# nrf7140_application register map
Vendor: Nordic Semiconductor; Series: nRF71; File version: 1
CPU: CM33 r0p4, little endian, MPU, FPU, 3 interrupt priority bits, 480 interrupts, 8 SAU regions
Registers are 32-bit, read-write, reset 0x0 unless marked. A register's access mark holds for its fields unless they carry their own. Offsets are from the block's base; [hi:lo] are bit positions; lines under a group give offsets from that group; {n}, {i} and the like mark numbered series.

## GLOBAL_GSI_NS (part 3 of 3) — GSI
Base 0x49008000
0x2000 CSI2 group — Unspecified
  0x00 VERSION reset 0x30313534 — Contains the version of DWC_mipi_csi2_host coded in 32-bit ASCII code.
    [31:0] VERSION ro — This field indicates the version of the DWC_mipi_csi2_host.
  0x04 NLANES reset 0x1 — Configures the number of active lanes that the DWC_mipi_csi2_host uses to receive the camera device data.
    [2:0] NLANES — This can only be updated when the PHY lane is in stopstate.Number of active data lanes:
      0=DATALANE1 (1 Data Lane); 1=DATALANE2 (2 Data Lanes); 2=DATALANE3 (3 Data Lanes); {v}=DATALANE{v+1} ({v+1} Data Lanes - Only on D-PHY) (v=3..7)
  0x08 CSI2RESETN — Controls the DWC_mipi_csi2_host logic reset state. When activated, the internal logic of the controller goes into the reset state. The configuration is not reset to default values with this register, instead, only the internal controller logic is affected.
    [0] CSI2RESETN — DWC_mipi_csi2_host reset output. Active Low.
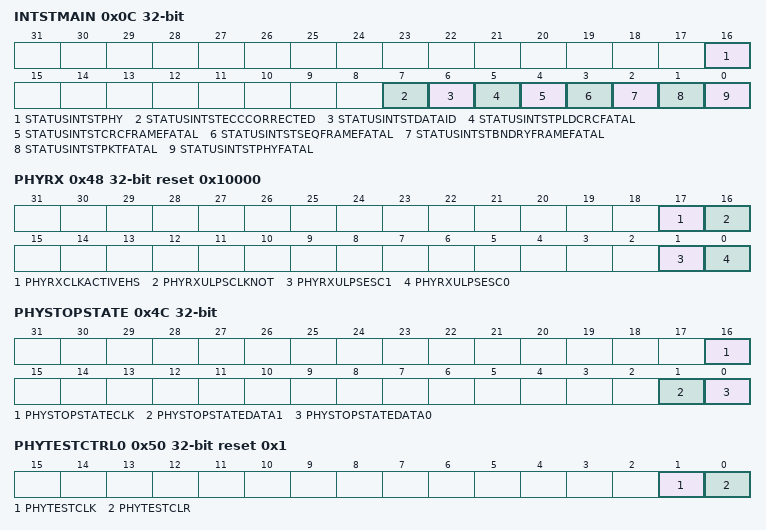
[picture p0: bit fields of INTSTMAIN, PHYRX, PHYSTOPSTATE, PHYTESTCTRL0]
  0x0C INTSTMAIN — Contains the status of individual interrupt sources, regardless of the contents of the associated interrupt mask registers, so it is possible to service the interrupt status registers by polling. Reading INT_ST_MAIN register clears the interrupt pin.
    [16] STATUSINTSTPHY ro — Status of int_st_phy.
    [7] STATUSINTSTECCCORRECTED ro — Status of int_st_ecc_corrected.
    [6] STATUSINTSTDATAID ro — Status of int_st_data_id.
    [5] STATUSINTSTPLDCRCFATAL ro — Status of int_st_pld_crc_fatal.
    [4] STATUSINTSTCRCFRAMEFATAL ro — Status of int_st_crc_frame_fatal.
    [3] STATUSINTSTSEQFRAMEFATAL ro — Status of int_st_seq_frame_fatal.
    [2] STATUSINTSTBNDRYFRAMEFATAL ro — Status of int_st_bndry_frame_fatal.
    [1] STATUSINTSTPKTFATAL ro — Status of int_st_pkt_fatal.
    [0] STATUSINTSTPHYFATAL ro — Status of int_st_phy_fatal.
  0x40 PHYSHUTDOWNZ — Controls the PHY Shutdown mode. In this state, the PHY sets the analog and digital circuitry in the Reset state.
    [0] PHYSHUTDOWNZ — Shutdown input. This line is used to place the complete macro in power down. All analog blocks are in power down mode and digital logic is cleared. Active Low.
  0x44 DPHYRSTZ — Controls the PHY Reset mode. In this state, the PHY sets the digital circuitry in the Reset State.
    [0] DPHYRSTZ — PHY reset output. Active Low.
  0x48 PHYRX reset 0x10000 — Contains the status of RX-related signals from PHY:
    [17] PHYRXCLKACTIVEHS ro — Indicates that D-PHY clock lane is actively receiving a DDR clock
    [16] PHYRXULPSCLKNOT ro — Active Low. This signal indicates that D-PHY Clock Lane module has entered the Ultra Low Power state
    [1] PHYRXULPSESC1 ro — Lane module 1 has entered the Ultra Low Power mode
    [0] PHYRXULPSESC0 ro — Lane module 0 has entered the Ultra Low Power mode.
  0x4C PHYSTOPSTATE — Contains the STOPSTATE signal status from PHY.
    [16] PHYSTOPSTATECLK ro — D-PHY Clock lane in Stop state
    [1] PHYSTOPSTATEDATA1 ro — Data lane 1 in Stop state
    [0] PHYSTOPSTATEDATA0 ro — Data lane 0 in Stop state.
  0x50 PHYTESTCTRL0 reset 0x1 — Control for vendor specific interface in the PHY.
    [1] PHYTESTCLK — Clock to capture testdin bus contents into the macro, with testen signal controlling the operation selection.
    [0] PHYTESTCLR — When active, performs vendor specific interface initialization.
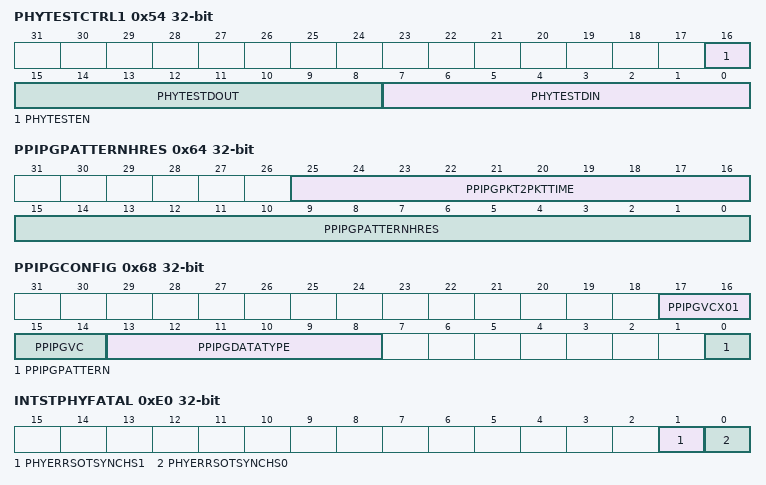
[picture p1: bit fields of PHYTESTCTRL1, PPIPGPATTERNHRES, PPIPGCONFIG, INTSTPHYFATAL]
  0x54 PHYTESTCTRL1 — Control for vendor specific interface in the PHY.
    [16] PHYTESTEN — When asserted high, it configures an address write operation on the falling edge of testclk. When asserted low, it configures a data write operation on the rising edge of testclk.
    [15:8] PHYTESTDOUT ro — Vendor-specific 8-bit data output for reading data and other probing functionalities.
    [7:0] PHYTESTDIN — Test interface 8-bit data input for programming internal registers and accessing test functionalities.
  0x60 PPIPGPATTERNVRES — This register configures the PPI pattern Generator's pattern vertical resolution.
    [15:0] PPIPGPATTERNVRES
  0x64 PPIPGPATTERNHRES — This register configures the PPI pattern Generator's pattern horizontal resolution.
    [25:16] PPIPGPKT2PKTTIME — This register configures the PPI pattern Generator's packet-to-packet time.
    [15:0] PPIPGPATTERNHRES — This register configures the PPI pattern Generator's pattern horizontal resolution.
  0x68 PPIPGCONFIG — This register configures the PPI pattern Generator.
    [17:16] PPIPGVCX01 — This register configures the PPI pattern Generator's virtual channel extension.
    [15:14] PPIPGVC — This register configures the PPI pattern Generator's virtual channel.
    [13:8] PPIPGDATATYPE — This register configures the PPI pattern Generator's data type.
    [0] PPIPGPATTERN — This register configures the PPI pattern Generator's pattern:
      0=VERTICAL (Vertical Pattern); 1=HORIZONTAL (Horizontal Pattern)
  0x6C PPIPGENABLE — This register enables PPI pattern Generator.
    [0] PPIPGENABLE
  0x70 PPIPGSTATUS — This register indicates PPI Pattern Generator Status.
    [0] PPIPGSTATUS ro — PPI Pattern Generator status:
      0=INACTIVE (PPI PG is inactive); 1=ACTIVE (PPI PG is running)
  0xC8 VCEXTENSION — This register activates extra bits for virtual channel. The Virtual Channel Extension (VCX) field is common to both options, but is a 2-bit field for D-PHY and a 3-bit field for C-PHY.
    [0] VCX — This field indicates status of Virtual Channel Extension:
  0xCC PHYCAL — Contains the CALIBRATION signal status from Synopsys D-PHY.
    [0] RXSKEWCALHS ro — A low-to-high transition on rxskewcalhs signal means that the PHY has initiated the de-skew calibration.
  0xE0 INTSTPHYFATAL — Groups the fatal interruptions caused by PHY Packet discarded.
    [1] PHYERRSOTSYNCHS1 ro — Start of transmission error on data lane 1 (no synchronization achieved)
    [0] PHYERRSOTSYNCHS0 ro — Start of transmission error on data lane 0 (no synchronization achieved).
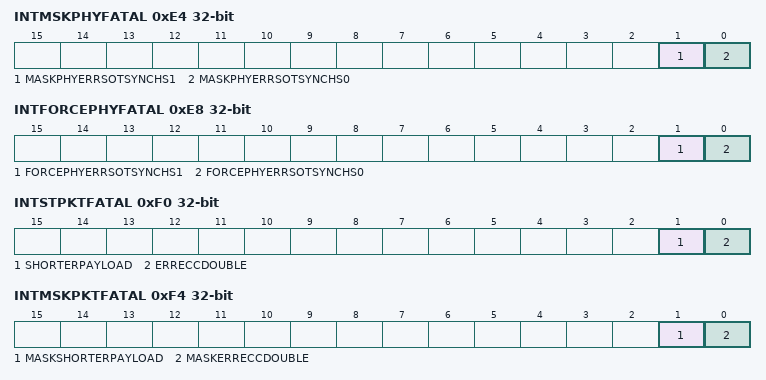
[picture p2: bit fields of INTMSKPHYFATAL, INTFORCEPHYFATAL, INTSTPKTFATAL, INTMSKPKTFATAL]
  0xE4 INTMSKPHYFATAL — Interrupt mask for INT_ST_PHY_FATAL controls which interrupt status bits trigger the interrupt pin. Bit at 1 - Enable the interrupt source. Bit at 0 - Interrupt source is masked.
    [1] MASKPHYERRSOTSYNCHS1 — Mask for phy_errsotsynchs_1
    [0] MASKPHYERRSOTSYNCHS0 — Mask for phy_errsotsynchs_0.
  0xE8 INTFORCEPHYFATAL — Interrupt Force register is used for test purposes, and allows triggering INT_ST_PHY_FATAL interrupt events individually, without the need to activate the conditions that trigger the interrupt sources, since it may be extremely complex to generate stimuli for that purpose. This register is auto-clear.
    [1] FORCEPHYERRSOTSYNCHS1, [0] FORCEPHYERRSOTSYNCHS0
  0xF0 INTSTPKTFATAL — Groups the fatal interruption related with Packet construction. Packet discarded.
    [1] SHORTERPAYLOAD ro — D-PHY mode: Reported greater WC than received, unrecoverable.
    [0] ERRECCDOUBLE ro — D-PHY mode: Header ECC contains at least 2 errors, unrecoverable.
  0xF4 INTMSKPKTFATAL — Interrupt mask for INT_ST_PKT_FATAL controls which interrupt status bits trigger the interrupt pin. Bit at 1 - Enable the interrupt source. Bit at 0 - Interrupt source is masked.
    [1] MASKSHORTERPAYLOAD — Mask for shorter_payload.
    [0] MASKERRECCDOUBLE — Mask for err_ecc_double.
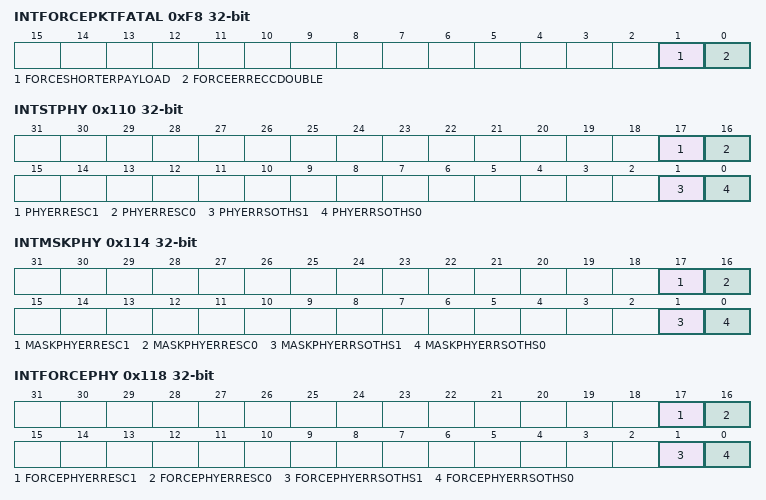
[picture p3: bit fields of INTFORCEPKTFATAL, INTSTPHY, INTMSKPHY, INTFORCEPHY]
  0xF8 INTFORCEPKTFATAL — Interrupt force register is used for test purposes, and allows triggering INT_ST_PKT_FATAL interrupt events individually, without the need to activate the conditions that trigger the interrupt sources, since it may be extremely complex to generate stimuli for that purpose. This register is auto-clear.
    [1] FORCESHORTERPAYLOAD, [0] FORCEERRECCDOUBLE
  0x110 INTSTPHY — Interruption caused by PHY.
    [17] PHYERRESC1 ro — Escape Entry Error on data lane 1
    [16] PHYERRESC0 ro — Escape Entry Error on data lane 0.
    [1] PHYERRSOTHS1 ro — Start of transmission error on data lane 1 (synchronization can still be achieved)
    [0] PHYERRSOTHS0 ro — Start of transmission error on data lane 0 (synchronization can still be achieved).
  0x114 INTMSKPHY — Interrupt mask for INT_ST_PHY controls which interrupt status bits trigger the interrupt pin. Bit at 1 - Enable the interrupt source. Bit at 0 - Interrupt source is masked.
    [17] MASKPHYERRESC1 — Mask for phy_erresc_1
    [16] MASKPHYERRESC0 — Mask for phy_erresc_0.
    [1] MASKPHYERRSOTHS1 — Mask for phy_errsoths_1
    [0] MASKPHYERRSOTHS0 — Mask for phy_errsoths_0.
  0x118 INTFORCEPHY — Interrupt force register is used for test purposes, and allows triggering INT_ST_PHY interrupt events individually. There is no need to activate the conditions that trigger the interrupt sources, because it may be extremely complex to generate stimuli for that purpose. This register is auto-clear.
    [17] FORCEPHYERRESC1, [16] FORCEPHYERRESC0, [1] FORCEPHYERRSOTHS1, [0] FORCEPHYERRSOTHS0
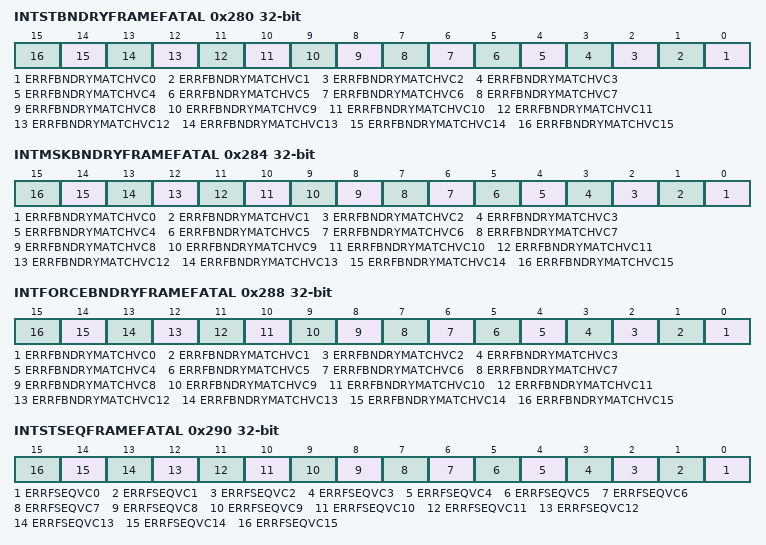
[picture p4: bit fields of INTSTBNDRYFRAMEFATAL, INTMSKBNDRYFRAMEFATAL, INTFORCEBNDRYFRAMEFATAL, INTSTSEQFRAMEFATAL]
  0x280 INTSTBNDRYFRAMEFATAL — Fatal interruption related with matching Frame Start with Frame End for a specific virtual channel.
    [n] ERRFBNDRYMATCHVC{n} ro (n=0..15) — Error matching Frame Start with Frame End for virtual channel {n}.
  0x284 INTMSKBNDRYFRAMEFATAL — Interrupt mask for INT_ST_BNDRY_FRAME_FATAL controls which interrupt status bits trigger the interrupt pin. Bit at 1 - Enable the interrupt source. Bit at 0 - Interrupt source is masked.
    [n] ERRFBNDRYMATCHVC{n} (n=0..15) — Mask for err_f_bndry_match_vc{n}.
  0x288 INTFORCEBNDRYFRAMEFATAL — Interrupt force register is used for test purposes, and allows triggering INT_ST_BNDRY_FRAME_FATAL interrupt events individually, without the need to activate the conditions that trigger the interrupt sources, since it may be extremely complex to generate stimuli for that purpose. This register is auto-clear.
    [n] ERRFBNDRYMATCHVC{n} (n=0..15) — Force err_f_bndry_match_vc{n}.
  0x290 INTSTSEQFRAMEFATAL — Fatal interruption related with incorrect Frame sequence for a specific virtual channel.
    [n] ERRFSEQVC{n} ro (n=0..15) — Incorrect Frame sequence detected in virtual channel {n}.
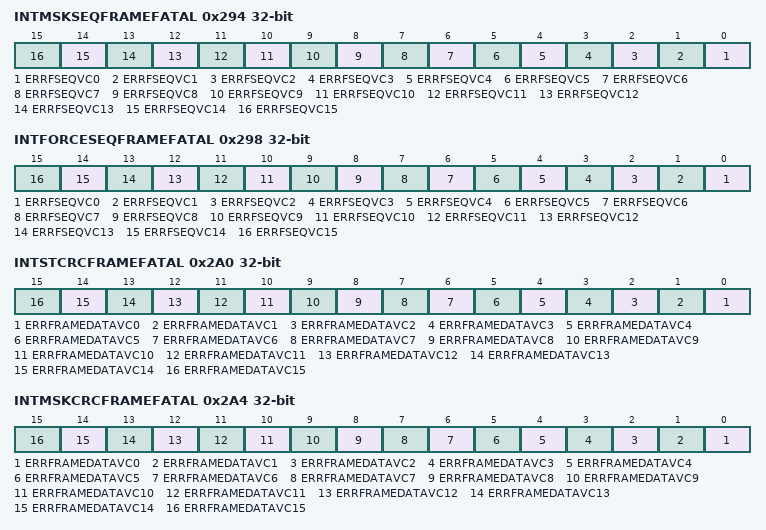
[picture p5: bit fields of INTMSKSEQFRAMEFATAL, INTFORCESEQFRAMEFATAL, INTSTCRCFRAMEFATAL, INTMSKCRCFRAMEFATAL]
  0x294 INTMSKSEQFRAMEFATAL — Interrupt mask for INT_ST_SEQ_FRAME_FATAL controls which interrupt status bits trigger the interrupt pin. Bit at 1 - Enable the interrupt source. Bit at 0 - Interrupt source is masked.
    [n] ERRFSEQVC{n} (n=0..15) — Mask for err_f_seq_vc{n}.
  0x298 INTFORCESEQFRAMEFATAL — Interrupt force register is used for test purposes, and allows triggering INT_ST_SEQ_FRAME_FATAL interrupt events individually. There is no need to activate the conditions that trigger the interrupt sources, because it may be extremely complex to generate stimuli for that purpose. This register is auto-clear.
    [n] ERRFSEQVC{n} (n=0..15) — Force err_f_seq_vc{n}.
  0x2A0 INTSTCRCFRAMEFATAL — Fatal interruption related with Frames with at least one CRC error for a specific virtual channel.
    [n] ERRFRAMEDATAVC{n} ro (n=0..15) — Last received Frame in virtual channel {n}, had at least one CRC error.
  0x2A4 INTMSKCRCFRAMEFATAL — Interrupt mask for INT_ST_CRC_FRAME_FATAL controls which interrupt status bits trigger the interrupt pin. Bit at 1 - Enable the interrupt source. Bit at 0 - Interrupt source is masked.
    [n] ERRFRAMEDATAVC{n} (n=0..15) — Mask for err_frame_data_vc{n}.
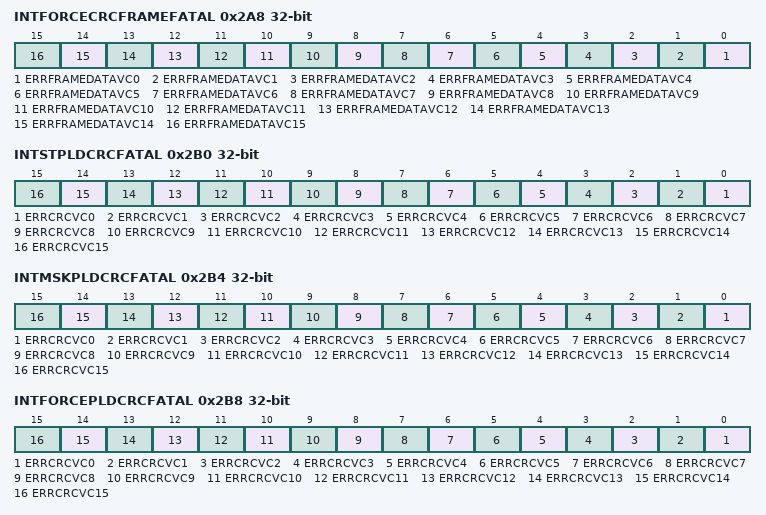
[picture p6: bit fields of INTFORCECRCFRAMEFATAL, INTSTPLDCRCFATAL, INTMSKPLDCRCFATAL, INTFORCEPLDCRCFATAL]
  0x2A8 INTFORCECRCFRAMEFATAL — Interrupt force register is used for test purposes, and allows triggering INT_ST_CRC_FRAME_FATAL interrupt events individually. There is no need to activate the conditions that trigger the interrupt sources, because it may be extremely complex to generate stimuli for that purpose. This register is auto-clear.
    [n] ERRFRAMEDATAVC{n} (n=0..15) — Force err_frame_data_vc{n}.
  0x2B0 INTSTPLDCRCFATAL — Fatal interruption related with Payload Checksum error.
    [n] ERRCRCVC{n} ro (n=0..15) — Payload Checksum error detected on virtual channel {n}.
  0x2B4 INTMSKPLDCRCFATAL — Interrupt mask for INT_ST_PLD_CRC_FATAL controls which interrupt status bits trigger the interrupt pin. Bit at 1 - Enable the interrupt source. Bit at 0 - Interrupt source is masked.
    [n] ERRCRCVC{n} (n=0..15) — Mask for err_crc_vc{n}.
  0x2B8 INTFORCEPLDCRCFATAL — Interrupt force register is used for test purposes, and allows triggering INT_ST_PLD_CRC_FATAL interrupt events individually. There is no need to activate the conditions that trigger the interrupt sources, because it may be extremely complex to generate stimuli for that purpose. This register is auto-clear.
    [n] ERRCRCVC{n} (n=0..15) — Force err_crc_vc{n}.
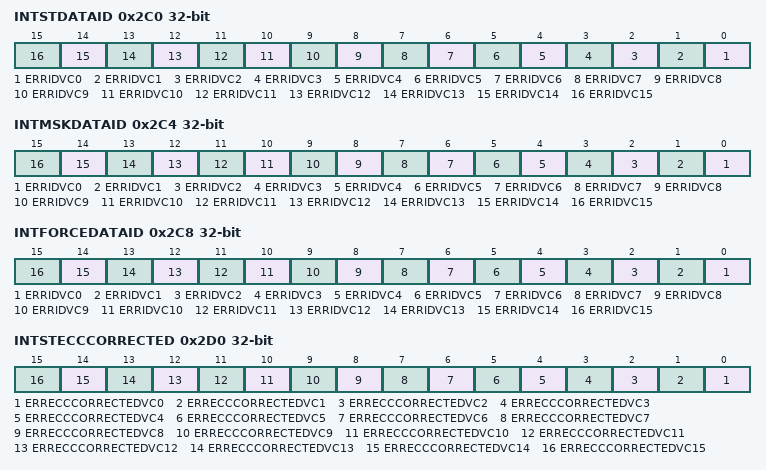
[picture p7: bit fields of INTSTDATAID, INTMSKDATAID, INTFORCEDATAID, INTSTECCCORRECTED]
  0x2C0 INTSTDATAID — Interruption related with unrecognized or unimplemented data type detected in a specific virtual channel.
    [n] ERRIDVC{n} ro (n=0..15) — Unrecognized or unimplemented data type detected in virtual channel {n}.
  0x2C4 INTMSKDATAID — Interrupt mask for INT_ST_DATA_ID controls which interrupt status bits trigger the interrupt pin. Bit at 1 - Enable the interrupt source. Bit at 0 - Interrupt source is masked.
    [n] ERRIDVC{n} (n=0..15) — Mask for err_id_vc{n}.
  0x2C8 INTFORCEDATAID — Interrupt force register is used for test purposes, and allows triggering INT_ST_DATA_ID interrupt events individually. There is no need to activate the conditions that trigger the interrupt sources, because it may be extremely complex to generate stimuli for that purpose. This register is auto-clear.
    [n] ERRIDVC{n} (n=0..15) — Force err_id_vc{n}.
  0x2D0 INTSTECCCORRECTED — Interruption related with header error detected and corrected for a specific virtual channel.
    [n] ERRECCCORRECTEDVC{n} ro (n=0..15) — D-PHY mode: Header error detected and corrected on virtual channel {n}.
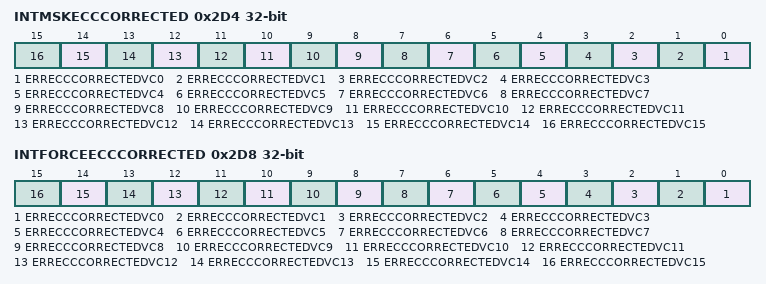
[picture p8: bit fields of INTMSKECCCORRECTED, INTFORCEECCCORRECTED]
  0x2D4 INTMSKECCCORRECTED — Interrupt mask for INT_ST_ECC_CORRECTED controls which interrupt status bits trigger the interrupt pin. Bit at 1 - Enable the interrupt source. Bit at 0 - Interrupt source is masked.
    [n] ERRECCCORRECTEDVC{n} (n=0..15) — Mask for err_ecc_corrected_vc{n}.
  0x2D8 INTFORCEECCCORRECTED — Interrupt force register is used for test purposes, and allows triggering INT_ST_ECC_CORRECTED interrupt events individually. There is no need to activate the conditions that trigger the interrupt sources, because it may be extremely complex to generate stimuli for that purpose. This register is auto-clear.
    [n] ERRECCCORRECTEDVC{n} (n=0..15) — Force err_ecc_corrected_vc{n}.
  0x300 SCRAMBLING — This register configures the De-scrambler block.
    [0] SCRAMBLEENABLE — Enables data de-scrambling on the controller side.
  0x304 SCRAMBLINGSEED1 reset 0x1008 — This register configures the seed used by De-scrambler block for lane 1
    [15:0] SCRAMBLESEEDLANE1 — Seed used by De-scrambler block for lane 1
  0x308 SCRAMBLINGSEED2 reset 0x1188 — This register configures the seed used by De-scrambler block for lane 2
    [15:0] SCRAMBLESEEDLANE2 — Seed used by De-scrambler block for lane 2
